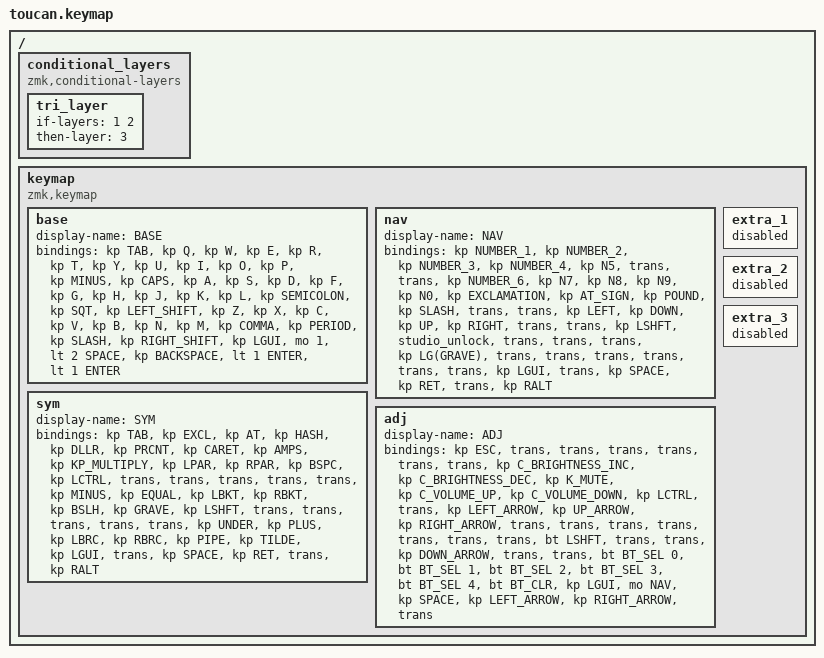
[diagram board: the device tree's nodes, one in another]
#include <behaviors.dtsi>
#include <dt-bindings/zmk/bt.h>
#include <dt-bindings/zmk/keys.h>

#define BASE 0
#define NAV  1
#define SYM  2
#define ADJ  3

/ {
    conditional_layers {
        compatible = "zmk,conditional-layers";

        tri_layer {
            if-layers = <1 2>;
            then-layer = <3>;
        };
    };

    keymap {
        compatible = "zmk,keymap";

        base {
            display-name = "BASE";
            bindings = <
&kp TAB  &kp Q  &kp W  &kp E  &kp R  &kp T  &kp Y  &kp U  &kp I  &kp O  &kp P  &kp MINUS  &kp CAPS  &kp A  &kp S  &kp D  &kp F  &kp G  &kp H  &kp J  &kp K  &kp L  &kp SEMICOLON  &kp SQT  &kp LEFT_SHIFT  &kp Z  &kp X  &kp C  &kp V  &kp B  &kp N  &kp M  &kp COMMA  &kp PERIOD  &kp SLASH  &kp RIGHT_SHIFT  &kp LGUI  &mo 1  &lt 2 SPACE  &kp BACKSPACE  &lt 1 ENTER  &lt 1 ENTER
            >;
        };

        nav {
            display-name = "NAV";
            bindings = <
&kp NUMBER_1  &kp NUMBER_2  &kp NUMBER_3  &kp NUMBER_4  &kp N5  &trans  &trans  &kp NUMBER_6  &kp N7  &kp N8  &kp N9  &kp N0  &kp EXCLAMATION  &kp AT_SIGN  &kp POUND  &kp SLASH  &trans  &trans  &kp LEFT  &kp DOWN  &kp UP  &kp RIGHT  &trans  &trans  &kp LSHFT  &studio_unlock  &trans  &trans  &trans  &kp LG(GRAVE)  &trans  &trans  &trans  &trans  &trans  &trans  &kp LGUI  &trans  &kp SPACE  &kp RET  &trans  &kp RALT
            >;
        };

        sym {
            display-name = "SYM";
            bindings = <
&kp TAB  &kp EXCL  &kp AT  &kp HASH  &kp DLLR  &kp PRCNT  &kp CARET  &kp AMPS  &kp KP_MULTIPLY  &kp LPAR  &kp RPAR  &kp BSPC  &kp LCTRL  &trans  &trans  &trans  &trans  &trans  &kp MINUS  &kp EQUAL  &kp LBKT  &kp RBKT  &kp BSLH  &kp GRAVE  &kp LSHFT  &trans  &trans  &trans  &trans  &trans  &kp UNDER  &kp PLUS  &kp LBRC  &kp RBRC  &kp PIPE  &kp TILDE  &kp LGUI  &trans  &kp SPACE  &kp RET  &trans  &kp RALT
            >;
        };

        adj {
            display-name = "ADJ";
            bindings = <
&kp ESC  &trans  &trans  &trans  &trans  &trans  &trans  &kp C_BRIGHTNESS_INC  &kp C_BRIGHTNESS_DEC  &kp K_MUTE  &kp C_VOLUME_UP  &kp C_VOLUME_DOWN  &kp LCTRL  &trans  &kp LEFT_ARROW  &kp UP_ARROW  &kp RIGHT_ARROW  &trans  &trans  &trans  &trans  &trans  &trans  &trans  &bt LSHFT  &trans  &trans  &kp DOWN_ARROW  &trans  &trans  &bt BT_SEL 0  &bt BT_SEL 1  &bt BT_SEL 2  &bt BT_SEL 3  &bt BT_SEL 4  &bt BT_CLR  &kp LGUI  &mo NAV  &kp SPACE  &kp LEFT_ARROW  &kp RIGHT_ARROW  &trans
            >;
        };

        extra_1 { status = "reserved"; };

        extra_2 { status = "reserved"; };

        extra_3 { status = "reserved"; };
    };
};
